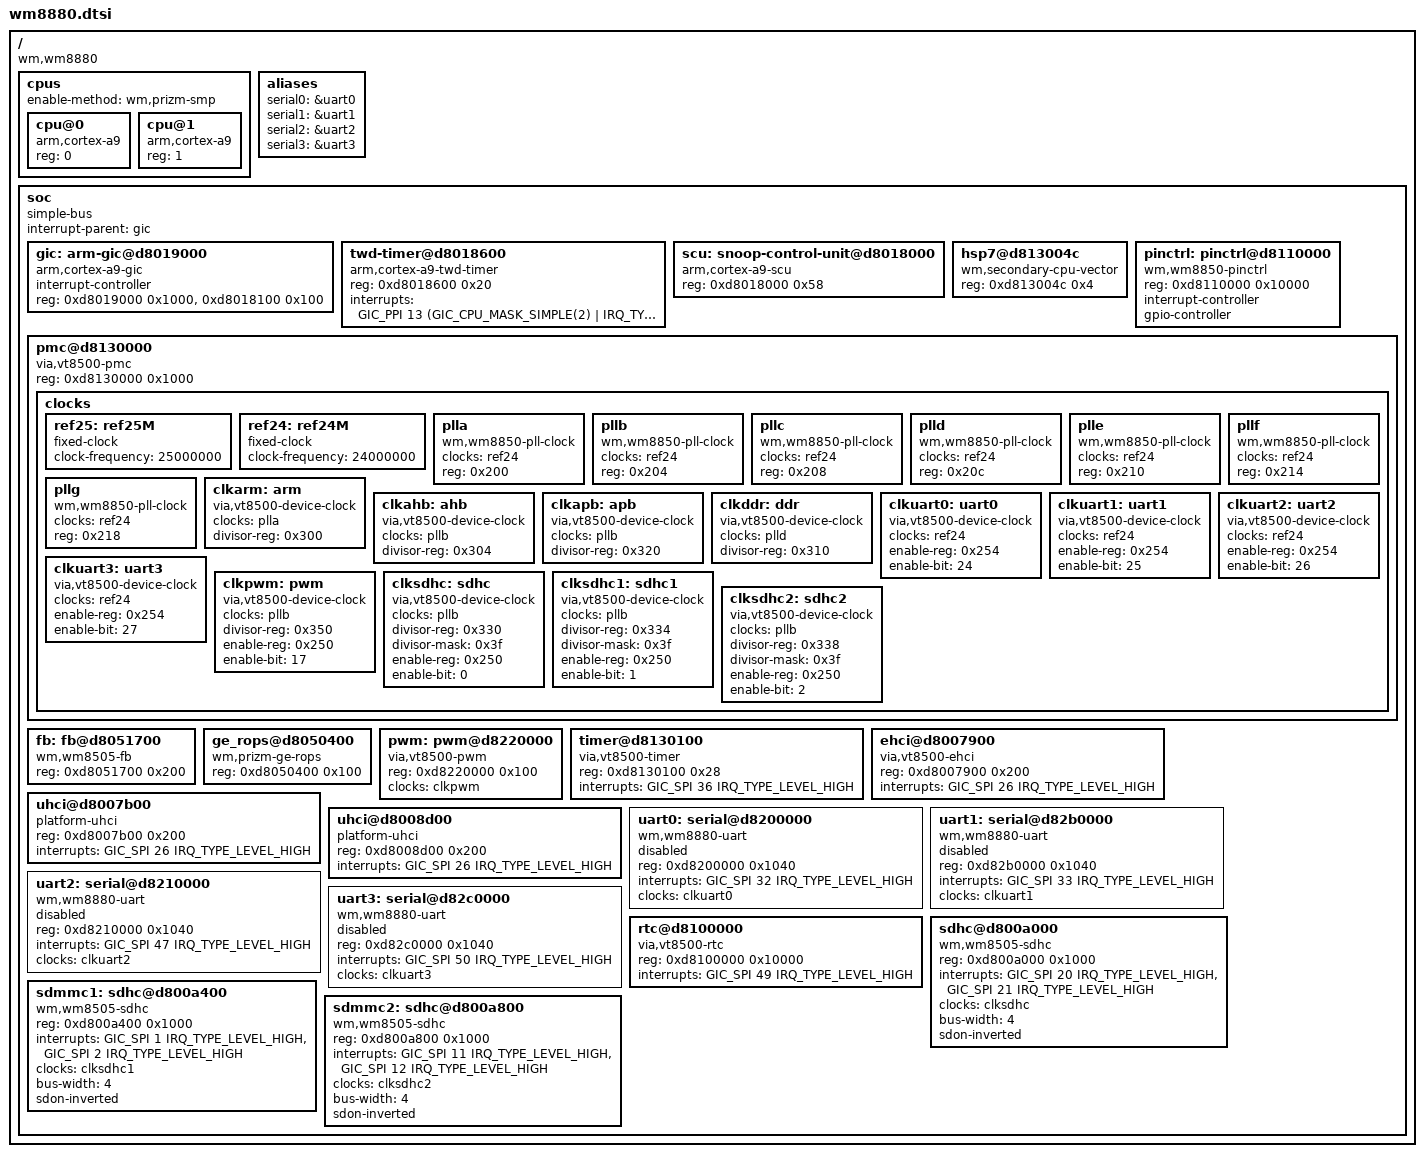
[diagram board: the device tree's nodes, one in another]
#include <dt-bindings/interrupt-controller/arm-gic.h>

#include "skeleton.dtsi"

/ {
	compatible = "wm,wm8880";

	cpus {
		#address-cells = <1>;
		#size-cells = <0>;
		enable-method = "wm,prizm-smp";

		cpu@0 {
			device_type = "cpu";
			compatible = "arm,cortex-a9";
			reg = <0>;
		};

		cpu@1 {
			device_type = "cpu";
			compatible = "arm,cortex-a9";
			reg = <1>;
		};
	};

	aliases {
		serial0 = &uart0;
		serial1 = &uart1;
		serial2 = &uart2;
		serial3 = &uart3;
	};

	soc {
		#address-cells = <1>;
		#size-cells = <1>;
		compatible = "simple-bus";
		ranges;
		interrupt-parent = <&gic>;

		gic: arm-gic@d8019000 {
			compatible = "arm,cortex-a9-gic";
			interrupt-controller;
			#interrupt-cells = <3>;
			reg = <0xd8019000 0x1000>,
			      <0xd8018100 0x100>;
		};

		twd-timer@d8018600 {
			compatible = "arm,cortex-a9-twd-timer";
			reg = <0xd8018600 0x20>;
			interrupts = <GIC_PPI 13
			  (GIC_CPU_MASK_SIMPLE(2) | IRQ_TYPE_LEVEL_HIGH)>;
		};

		scu: snoop-control-unit@d8018000 {
			compatible = "arm,cortex-a9-scu";
			reg = <0xd8018000 0x58>;
		};

		/* PMC Hibernation scratch pad register 7 is the reset vector for CPU1 */
		hsp7@d813004c {
			compatible = "wm,secondary-cpu-vector";
			reg = <0xd813004c 0x4>;
		};

		pinctrl: pinctrl@d8110000 {
			compatible = "wm,wm8850-pinctrl";
			reg = <0xd8110000 0x10000>;
			interrupt-controller;
			#interrupt-cells = <2>;
			gpio-controller;
			#gpio-cells = <2>;
		};

		pmc@d8130000 {
			compatible = "via,vt8500-pmc";
			reg = <0xd8130000 0x1000>;

			clocks {
				#address-cells = <1>;
				#size-cells = <0>;

				ref25: ref25M {
					#clock-cells = <0>;
					compatible = "fixed-clock";
					clock-frequency = <25000000>;
				};

				ref24: ref24M {
					#clock-cells = <0>;
					compatible = "fixed-clock";
					clock-frequency = <24000000>;
				};

				plla: plla {
					#clock-cells = <0>;
					compatible = "wm,wm8850-pll-clock";
					clocks = <&ref24>;
					reg = <0x200>;
				};

				pllb: pllb {
					#clock-cells = <0>;
					compatible = "wm,wm8850-pll-clock";
					clocks = <&ref24>;
					reg = <0x204>;
				};

				pllc: pllc {
					#clock-cells = <0>;
					compatible = "wm,wm8850-pll-clock";
					clocks = <&ref24>;
					reg = <0x208>;
				};

				plld: plld {
					#clock-cells = <0>;
					compatible = "wm,wm8850-pll-clock";
					clocks = <&ref24>;
					reg = <0x20c>;
				};

				plle: plle {
					#clock-cells = <0>;
					compatible = "wm,wm8850-pll-clock";
					clocks = <&ref24>;
					reg = <0x210>;
				};

				pllf: pllf {
					#clock-cells = <0>;
					compatible = "wm,wm8850-pll-clock";
					clocks = <&ref24>;
					reg = <0x214>;
				};

				pllg: pllg {
					#clock-cells = <0>;
					compatible = "wm,wm8850-pll-clock";
					clocks = <&ref24>;
					reg = <0x218>;
				};

				clkarm: arm {
					#clock-cells = <0>;
					compatible = "via,vt8500-device-clock";
					clocks = <&plla>;
					divisor-reg = <0x300>;
				};

				clkahb: ahb {
					#clock-cells = <0>;
					compatible = "via,vt8500-device-clock";
					clocks = <&pllb>;
					divisor-reg = <0x304>;
				};

				clkapb: apb {
					#clock-cells = <0>;
					compatible = "via,vt8500-device-clock";
					clocks = <&pllb>;
					divisor-reg = <0x320>;
				};

				clkddr: ddr {
					#clock-cells = <0>;
					compatible = "via,vt8500-device-clock";
					clocks = <&plld>;
					divisor-reg = <0x310>;
				};

				clkuart0: uart0 {
					#clock-cells = <0>;
					compatible = "via,vt8500-device-clock";
					clocks = <&ref24>;
					enable-reg = <0x254>;
					enable-bit = <24>;
				};

				clkuart1: uart1 {
					#clock-cells = <0>;
					compatible = "via,vt8500-device-clock";
					clocks = <&ref24>;
					enable-reg = <0x254>;
					enable-bit = <25>;
				};

                                clkuart2: uart2 {
                                        #clock-cells = <0>;
                                        compatible = "via,vt8500-device-clock";
                                        clocks = <&ref24>;
                                        enable-reg = <0x254>;
                                        enable-bit = <26>;
                                };

                                clkuart3: uart3 {
                                        #clock-cells = <0>;
                                        compatible = "via,vt8500-device-clock";
                                        clocks = <&ref24>;
                                        enable-reg = <0x254>;
                                        enable-bit = <27>;
                                };

				clkpwm: pwm {
					#clock-cells = <0>;
					compatible = "via,vt8500-device-clock";
					clocks = <&pllb>;
					divisor-reg = <0x350>;
					enable-reg = <0x250>;
					enable-bit = <17>;
				};

				clksdhc: sdhc {
					#clock-cells = <0>;
					compatible = "via,vt8500-device-clock";
					clocks = <&pllb>;
					divisor-reg = <0x330>;
					divisor-mask = <0x3f>;
					enable-reg = <0x250>;
					enable-bit = <0>;
				};

				clksdhc1: sdhc1 {
					#clock-cells = <0>;
					compatible = "via,vt8500-device-clock";
					clocks = <&pllb>;
					divisor-reg = <0x334>;
					divisor-mask = <0x3f>;
					enable-reg = <0x250>;
					enable-bit = <1>;
				};

				clksdhc2: sdhc2 {
					#clock-cells = <0>;
					compatible = "via,vt8500-device-clock";
					clocks = <&pllb>;
					divisor-reg = <0x338>;
					divisor-mask = <0x3f>;
					enable-reg = <0x250>;
					enable-bit = <2>;
				};
			};
		};

		fb: fb@d8051700 {
			compatible = "wm,wm8505-fb";
			reg = <0xd8051700 0x200>;
		};

		ge_rops@d8050400 {
			compatible = "wm,prizm-ge-rops";
			reg = <0xd8050400 0x100>;
		};

		pwm: pwm@d8220000 {
			#pwm-cells = <3>;
			compatible = "via,vt8500-pwm";
			reg = <0xd8220000 0x100>;
			clocks = <&clkpwm>;
		};

		timer@d8130100 {
			compatible = "via,vt8500-timer";
			reg = <0xd8130100 0x28>;
			interrupts = <GIC_SPI 36 IRQ_TYPE_LEVEL_HIGH>;
		};

		ehci@d8007900 {
			compatible = "via,vt8500-ehci";
			reg = <0xd8007900 0x200>;
			interrupts = <GIC_SPI 26 IRQ_TYPE_LEVEL_HIGH>;
		};

		uhci@d8007b00 {
			compatible = "platform-uhci";
			reg = <0xd8007b00 0x200>;
			interrupts = <GIC_SPI 26 IRQ_TYPE_LEVEL_HIGH>;
		};

		uhci@d8008d00 {
			compatible = "platform-uhci";
			reg = <0xd8008d00 0x200>;
			interrupts = <GIC_SPI 26 IRQ_TYPE_LEVEL_HIGH>;
		};

		uart0: serial@d8200000 {
			compatible = "wm,wm8880-uart";
			reg = <0xd8200000 0x1040>;
			interrupts = <GIC_SPI 32 IRQ_TYPE_LEVEL_HIGH>;
			clocks = <&clkuart0>;
			status = "disabled";
		};

		uart1: serial@d82b0000 {
			compatible = "wm,wm8880-uart";
			reg = <0xd82b0000 0x1040>;
			interrupts = <GIC_SPI 33 IRQ_TYPE_LEVEL_HIGH>;
			clocks = <&clkuart1>;
			status = "disabled";
		};

                uart2: serial@d8210000 {
			compatible = "wm,wm8880-uart";
			reg = <0xd8210000 0x1040>;
			interrupts = <GIC_SPI 47 IRQ_TYPE_LEVEL_HIGH>;
			clocks = <&clkuart2>;
			status = "disabled";
                };

                uart3: serial@d82c0000 {
			compatible = "wm,wm8880-uart";
			reg = <0xd82c0000 0x1040>;
			interrupts = <GIC_SPI 50 IRQ_TYPE_LEVEL_HIGH>;
			clocks = <&clkuart3>;
			status = "disabled";
                };

		rtc@d8100000 {
			compatible = "via,vt8500-rtc";
			reg = <0xd8100000 0x10000>;
			interrupts = <GIC_SPI 49 IRQ_TYPE_LEVEL_HIGH>;
		};

		sdhc@d800a000 {
			compatible = "wm,wm8505-sdhc";
			reg = <0xd800a000 0x1000>;
			interrupts = <GIC_SPI 20 IRQ_TYPE_LEVEL_HIGH>,
				     <GIC_SPI 21 IRQ_TYPE_LEVEL_HIGH>;
			clocks = <&clksdhc>;
			bus-width = <4>;
			sdon-inverted;
		};

		sdmmc1: sdhc@d800a400 {
			compatible = "wm,wm8505-sdhc";
			reg = <0xd800a400 0x1000>;
			interrupts = <GIC_SPI 1 IRQ_TYPE_LEVEL_HIGH>,
				     <GIC_SPI 2 IRQ_TYPE_LEVEL_HIGH>;
			clocks = <&clksdhc1>;
			bus-width = <4>;
			sdon-inverted;
		};

		sdmmc2: sdhc@d800a800 {
			compatible = "wm,wm8505-sdhc";
			reg = <0xd800a800 0x1000>;
			interrupts = <GIC_SPI 11 IRQ_TYPE_LEVEL_HIGH>,
				     <GIC_SPI 12 IRQ_TYPE_LEVEL_HIGH>;
			clocks = <&clksdhc2>;
			bus-width = <4>;
			sdon-inverted;
		};
	};
};
